# lpc register map
Vendor: Texas Instruments
Peripheral module from a debugger description file (folder tm4e1231h6zrb).
Registers are 32-bit, read-write, no defined reset value unless marked. A register's access mark holds for its fields unless they carry their own. Offsets are as the file gives them; lines under a group give offsets from that group; [hi:lo] are bit positions; {n}, {i} and the like mark numbered series; 'fields as' and 'values as' point back to an identical list; <NAME> marks a mode.

## LPC0 — LPC register addresses
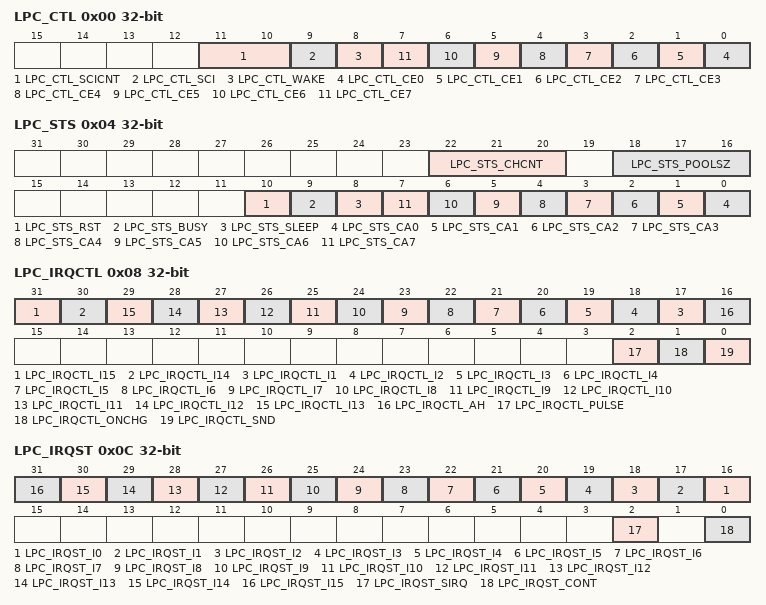
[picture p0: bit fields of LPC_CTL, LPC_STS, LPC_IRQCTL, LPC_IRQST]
0x00 LPC_CTL — LPC Control
  [11:10] LPC_CTL_SCICNT — LPC0SCI Pulse Length
    0=1-clock pulse; 1=2-clock pulse; 2=4-clock pulse; 3=8-clock pulse
  [9] LPC_CTL_SCI — Start LPC0SCI Pulse
  [8] LPC_CTL_WAKE — Wake or Keep Awake the LPC Bus
  [n] LPC_CTL_CE{n} (n=0..7) — Enable Channel {n}
0x04 LPC_STS ro — LPC Status
  [22:20] LPC_STS_CHCNT — Number of Channels
  [18:16] LPC_STS_POOLSZ — Register Pool Size
    1=256 bytes; 2=512 bytes; 3=768 bytes; 4=1024 bytes
  [10] LPC_STS_RST — LPC Bus is in Reset
  [9] LPC_STS_BUSY — LPC is Busy
  [8] LPC_STS_SLEEP — Sleep Mode
  [n] LPC_STS_CA{n} (n=0..7) — Channel {n} Active
0x08 LPC_IRQCTL — LPC IRQ Control
  [31] LPC_IRQCTL_I15 — Manual IRQ15 State
  [30] LPC_IRQCTL_I14 — Manual IRQ14 State
  [n+16] LPC_IRQCTL_I{n} (n=1..13) — Manual IIRQ{n} State
  [16] LPC_IRQCTL_AH — Active High Control
  [2] LPC_IRQCTL_PULSE — Pulse IRQ States
  [1] LPC_IRQCTL_ONCHG — Initiate on Change
  [0] LPC_IRQCTL_SND — Initiate Immediately
0x0C LPC_IRQST ro — LPC IRQ Status
  [n+16] LPC_IRQST_I{n} (n=0..15) — IRQ{n} State
  [2] LPC_IRQST_SIRQ — SERIRQ Transaction Frame Being Processed
  [0] LPC_IRQST_CONT — SERIRQ Continuous Mode
0x10 LPC_CH0CTL — LPC Channel 0 Control
  [31:28] LPC_CH0CTL_IRQSEL2 — IRQ Select 2
  [27:24] LPC_CH0CTL_IRQSEL1 — IRQ Select 1
  [23:20] LPC_CH0CTL_IRQSEL0 — IRQ Select 0
  [19] LPC_CH0CTL_IRQEN2 — IRQ Enable 2
  [19] LPC_CH0CTL_CX — IRQ Enable 2
  [18] LPC_CH0CTL_IRQEN1 — IRQ Enable 1
  [17:16] LPC_CH0CTL_IRQEN0 — IRQ Enable 0
    0=LPC_CH0CTL_IRQEN0_DIS (Trigger disabled); 1=LPC_CH0CTL_IRQEN0_TRIG1 (Trigger 1); 2=LPC_CH0CTL_IRQEN0_TRIG2 (Trigger 2); 3=LPC_CH0CTL_IRQEN0_TRIG3 (Trigger 3)
  [15] LPC_CH0CTL_ARBDIS — Arbitration Disabled
  [13:5] LPC_CH0CTL_OFFSET — Base Offset in Register Pool
  [4:2] LPC_CH0CTL_AMASK — Address Mask for Ranges
    0=4 bytes; 1=8 bytes; 2=16 bytes; 3=32 bytes; 4=64 bytes; 5=128 bytes; 6=256 bytes; 7=512 bytes
  [0] LPC_CH0CTL_TYPE — Channel Type
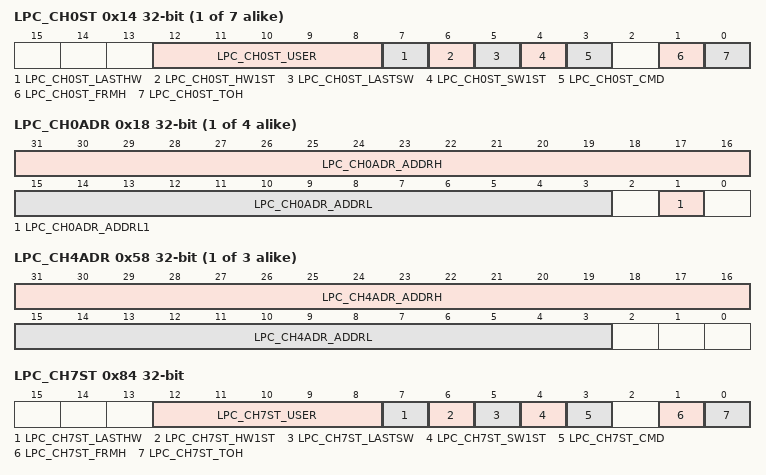
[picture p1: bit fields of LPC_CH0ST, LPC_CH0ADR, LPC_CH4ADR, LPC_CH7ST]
{0x14+0x10*i} LPC_CH{i}ST (i=0..6) — LPC Channel {i} Status
  [12:8] LPC_CH{i}ST_USER — User Data
  [7] LPC_CH{i}ST_LASTHW — Last Host Write
  [6] LPC_CH{i}ST_HW1ST — Host Wrote First
  [5] LPC_CH{i}ST_LASTSW — Last Slave Write
  [4] LPC_CH{i}ST_SW1ST — Slave Wrote First
  [3] LPC_CH{i}ST_CMD — Command or Data
  [1] LPC_CH{i}ST_FRMH — From-Host Transaction
  [0] LPC_CH{i}ST_TOH — To-Host Transaction
{0x18+0x10*i} LPC_CH{i}ADR (i=0..3) — LPC Channel {i} Address
  [31:16] LPC_CH{i}ADR_ADDRH — Upper Address Match
  [15:3] LPC_CH{i}ADR_ADDRL — Lower Address Match
  [1] LPC_CH{i}ADR_ADDRL1 — Endpoint Match Bit 1
0x20 LPC_CH1CTL — LPC Channel 1 Control
  [31:28] LPC_CH1CTL_IRQSEL2 — IRQ Select 2
  [27:24] LPC_CH1CTL_IRQSEL1 — IRQ Select 1
  [23:20] LPC_CH1CTL_IRQSEL0 — IRQ Select 0
  [19] LPC_CH1CTL_IRQEN2 — IRQ Enable 2
  [19] LPC_CH1CTL_CX — IRQ Enable 2
  [18] LPC_CH1CTL_IRQEN1 — IRQ Enable 1
  [17:16] LPC_CH1CTL_IRQEN0 — IRQ Enable 0
    0=LPC_CH1CTL_IRQEN0_DIS (Trigger disabled); 1=LPC_CH1CTL_IRQEN0_TRIG1 (Trigger 1); 2=LPC_CH1CTL_IRQEN0_TRGI2 (Trigger 2); 3=LPC_CH1CTL_IRQEN0_TRGI3 (Trigger 3)
  [15] LPC_CH1CTL_ARBDIS — Arbitration Disabled
  [13:5] LPC_CH1CTL_OFFSET — Base Offset in Register Pool
  [4:2] LPC_CH1CTL_AMASK — Address Mask for Ranges
    values as LPC_CH0CTL.LPC_CH0CTL_AMASK
  [0] LPC_CH1CTL_TYPE — Channel Type
0x30 LPC_CH2CTL — LPC Channel 2 Control
  [31:28] LPC_CH2CTL_IRQSEL2 — IRQ Select 2
  [27:24] LPC_CH2CTL_IRQSEL1 — IRQ Select 1
  [23:20] LPC_CH2CTL_IRQSEL0 — IRQ Select 0
  [19] LPC_CH2CTL_CX — IRQ Enable 2
  [19] LPC_CH2CTL_IRQEN2 — IRQ Enable 2
  [18] LPC_CH2CTL_IRQEN1 — IRQ Enable 1
  [17:16] LPC_CH2CTL_IRQEN0 — IRQ Enable 0
    0=LPC_CH2CTL_IRQEN0_DIS (Trigger disabled); 1=LPC_CH2CTL_IRQEN0_TRIG1 (Trigger 1); 2=LPC_CH2CTL_IRQEN0_TRIG2 (Trigger 2); 3=LPC_CH2CTL_IRQEN0_TRIG3 (Trigger 3)
  [15] LPC_CH2CTL_ARBDIS — Arbitration Disabled
  [13:5] LPC_CH2CTL_OFFSET — Base Offset in Register Pool
  [4:2] LPC_CH2CTL_AMASK — Address Mask for Ranges
    values as LPC_CH0CTL.LPC_CH0CTL_AMASK
  [0] LPC_CH2CTL_TYPE — Channel Type
0x40 LPC_CH3CTL — LPC Channel 3 Control
  [31:28] LPC_CH3CTL_IRQSEL2 — IRQ Select 2
  [27:24] LPC_CH3CTL_IRQSEL1 — IRQ Select 1
  [23:20] LPC_CH3CTL_IRQSEL0 — IRQ Select 0
  [19] LPC_CH3CTL_IRQEN2 — IRQ Enable 2
  [19] LPC_CH3CTL_CX — IRQ Enable 2
  [18] LPC_CH3CTL_IRQEN1 — IRQ Enable 1
  [17:16] LPC_CH3CTL_IRQEN0 — IRQ Enable 0
    0=LPC_CH3CTL_IRQEN0_DIS (Trigger disabled); 1=LPC_CH3CTL_IRQEN0_TRIG1 (Trigger 1); 2=LPC_CH3CTL_IRQEN0_TRIG2 (Trigger 2); 3=LPC_CH3CTL_IRQEN0_TRIG3 (Trigger 3)
  [15] LPC_CH3CTL_ARBDIS — Arbitration Disabled
  [13:5] LPC_CH3CTL_OFFSET — Base Offset in Register Pool
  [4:2] LPC_CH3CTL_AMASK — Address Mask for Ranges
    values as LPC_CH0CTL.LPC_CH0CTL_AMASK
  [0] LPC_CH3CTL_TYPE — Channel Type
0x50 LPC_CH4CTL — LPC Channel 4 Control
  [31:28] LPC_CH4CTL_IRQSEL2 — IRQ Select 2
  [27:24] LPC_CH4CTL_IRQSEL1 — IRQ Select 1
  [23:20] LPC_CH4CTL_IRQSEL0 — IRQ Select 0
  [19] LPC_CH4CTL_CX — IRQ Enable 2
  [19] LPC_CH4CTL_IRQEN2 — IRQ Enable 2
  [18] LPC_CH4CTL_IRQEN1 — IRQ Enable 1
  [17:16] LPC_CH4CTL_IRQEN0 — IRQ Enable 0
    0=LPC_CH4CTL_IRQEN0_DIS (Trigger disabled); 1=LPC_CH4CTL_IRQEN0_TRIG1 (Trigger 1); 2=LPC_CH4CTL_IRQEN0_TRIG2 (Trigger 2); 3=LPC_CH4CTL_IRQEN0_TRIG3 (Trigger 3)
  [15] LPC_CH4CTL_ARBDIS — Arbitration Disabled
  [13:5] LPC_CH4CTL_OFFSET — Base Offset in Register Pool
  [4:2] LPC_CH4CTL_AMASK — Address Mask for Ranges
    values as LPC_CH0CTL.LPC_CH0CTL_AMASK
  [0] LPC_CH4CTL_TYPE — Channel Type
{0x18+0x10*i} LPC_CH{i}ADR (i=4..6) — LPC Channel {i} Address
  [31:16] LPC_CH{i}ADR_ADDRH — Upper Address Match
  [15:3] LPC_CH{i}ADR_ADDRL — Lower Address Match
0x60 LPC_CH5CTL — LPC Channel 5 Control
  [31:28] LPC_CH5CTL_IRQSEL2 — IRQ Select 2
  [27:24] LPC_CH5CTL_IRQSEL1 — IRQ Select 1
  [23:20] LPC_CH5CTL_IRQSEL0 — IRQ Select 0
  [19] LPC_CH5CTL_IRQEN2 — IRQ Enable 2
  [19] LPC_CH5CTL_CX — IRQ Enable 2
  [18] LPC_CH5CTL_IRQEN1 — IRQ Enable 1
  [17:16] LPC_CH5CTL_IRQEN0 — IRQ Enable 0
    0=LPC_CH5CTL_IRQEN0_DIS (Trigger disabled); 1=LPC_CH5CTL_IRQEN0_TRIG1 (Trigger 1); 2=LPC_CH5CTL_IRQEN0_TRIG2 (Trigger 2); 3=LPC_CH5CTL_IRQEN0_TRIG3 (Trigger 3)
  [15] LPC_CH5CTL_ARBDIS — Arbitration Disabled
  [13:5] LPC_CH5CTL_OFFSET — Base Offset in Register Pool
  [4:2] LPC_CH5CTL_AMASK — Address Mask for Ranges
    values as LPC_CH0CTL.LPC_CH0CTL_AMASK
  [0] LPC_CH5CTL_TYPE — Channel Type
0x70 LPC_CH6CTL — LPC Channel 6 Control
  [31:28] LPC_CH6CTL_IRQSEL2 — IRQ Select 2
  [27:24] LPC_CH6CTL_IRQSEL1 — IRQ Select 1
  [23:20] LPC_CH6CTL_IRQSEL0 — IRQ Select 0
  [19] LPC_CH6CTL_CX — IRQ Enable 2
  [19] LPC_CH6CTL_IRQEN2 — IRQ Enable 2
  [18] LPC_CH6CTL_IRQEN1 — IRQ Enable 1
  [17:16] LPC_CH6CTL_IRQEN0 — IRQ Enable 0
    0=LPC_CH6CTL_IRQEN0_DIS (Trigger disabled); 1=LPC_CH6CTL_IRQEN0_TRIG1 (Trigger 1); 2=LPC_CH6CTL_IRQEN0_TRIG2 (Trigger 2); 3=LPC_CH6CTL_IRQEN0_TRIG3 (Trigger 3)
  [15] LPC_CH6CTL_ARBDIS — Arbitration Disabled
  [13:5] LPC_CH6CTL_OFFSET — Base Offset in Register Pool
  [4:2] LPC_CH6CTL_AMASK — Address Mask for Ranges
    values as LPC_CH0CTL.LPC_CH0CTL_AMASK
  [0] LPC_CH6CTL_TYPE — Channel Type
0x80 LPC_CH7CTL — LPC Channel 7 / COMx Control
  [31:28] LPC_CH7CTL_IRQSEL2 — IRQ Select 2
  [27:24] LPC_CH7CTL_IRQSEL1 — IRQ Select 1
  [23:20] LPC_CH7CTL_IRQSEL0 — IRQ Select 0
  [19] LPC_CH7CTL_CX — IRQ Enable 2
  [19] LPC_CH7CTL_IRQEN2 — IRQ Enable 2
  [18] LPC_CH7CTL_IRQEN1 — IRQ Enable 1
  [17:16] LPC_CH7CTL_IRQEN0 — IRQ Enable 0
    0=LPC_CH7CTL_IRQEN0_AUTO (Trigger disabled); 1=LPC_CH7CTL_IRQEN0_MST (Trigger 1); 2=LPC_CH7CTL_IRQEN0_SLV (Trigger 2); 3=LPC_CH7CTL_IRQEN0_TRIG3 (Trigger 3)
  [15] LPC_CH7CTL_ARBDIS — Arbitration Disabled
  [13:5] LPC_CH7CTL_OFFSET — Base Offset in Register Pool
  [4:2] LPC_CH7CTL_AMASK — Address Mask for Ranges
    values as LPC_CH0CTL.LPC_CH0CTL_AMASK
  [0] LPC_CH7CTL_TYPE — Channel Type
0x84 LPC_CH7ST — LPC Channel 7 / COMx Status
  [12:8] LPC_CH7ST_USER — User Data
  [7] LPC_CH7ST_LASTHW — Last Host Write
  [6] LPC_CH7ST_HW1ST — Host Wrote First
  [5] LPC_CH7ST_LASTSW — Last Slave Write
  [4] LPC_CH7ST_SW1ST — Slave Wrote First
  [3] LPC_CH7ST_CMD — Command or Data
  [1] LPC_CH7ST_FRMH — From-Host Transaction
  [0] LPC_CH7ST_TOH — To-Host Transaction
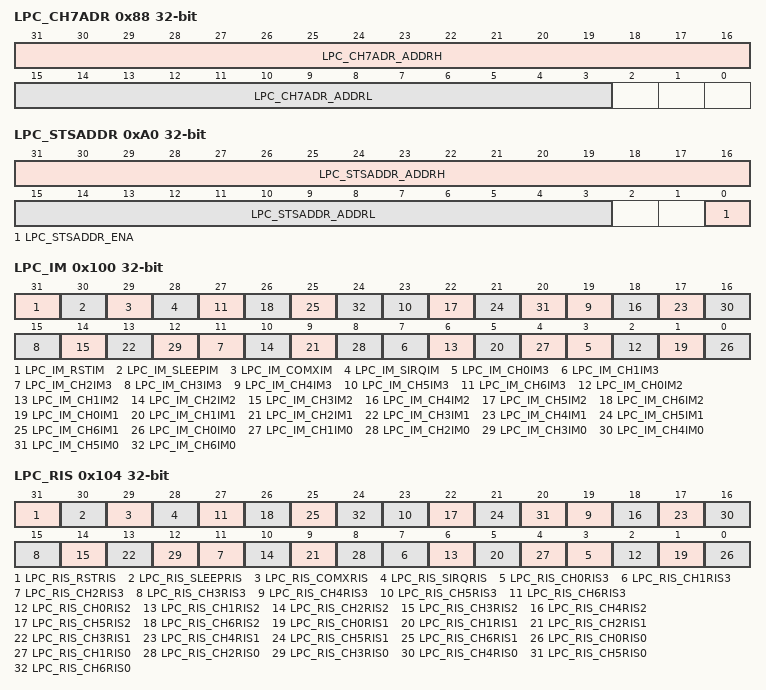
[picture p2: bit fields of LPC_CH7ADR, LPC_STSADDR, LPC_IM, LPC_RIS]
0x88 LPC_CH7ADR — LPC Channel 7 / COMx Address
  [31:16] LPC_CH7ADR_ADDRH — Upper Address Match
  [15:3] LPC_CH7ADR_ADDRL — Lower Address Match
0xA0 LPC_STSADDR — LPC Status Block Address
  [31:16] LPC_STSADDR_ADDRH — Upper Address Match
  [15:3] LPC_STSADDR_ADDRL — Lower Address Match
  [0] LPC_STSADDR_ENA — Enable Status Block
0x100 LPC_IM — LPC Interrupt Mask
  [31] LPC_IM_RSTIM — Reset State Interrupt Mask
  [30] LPC_IM_SLEEPIM — Sleep State Interrupt Mask
  [29] LPC_IM_COMXIM — COMx Interrupt Mask
  [28] LPC_IM_SIRQIM — SERIRQ Frame Complete Interrupt Mask
  [4n+3] LPC_IM_CH{n}IM3 (n=0..6) — Channel {n} Interrupt Mask 3
  [4n+2] LPC_IM_CH{n}IM2 (n=0..6) — Channel {n} Interrupt Mask 2
  [4n+1] LPC_IM_CH{n}IM1 (n=0..6) — Channel {n} Interrupt Mask 1
  [4n] LPC_IM_CH{n}IM0 (n=0..6) — Channel {n} Interrupt Mask 0
0x104 LPC_RIS ro — LPC Raw Interrupt Status
  [31] LPC_RIS_RSTRIS — Reset State Raw Interrupt Status
  [30] LPC_RIS_SLEEPRIS — Sleep State Raw Interrupt Status
  [29] LPC_RIS_COMXRIS — COMx Raw Interrupt Status
  [28] LPC_RIS_SIRQRIS — SERIRQ Frame Complete Raw Interrupt Status
  [4n+3] LPC_RIS_CH{n}RIS3 (n=0..6) — Channel {n} Raw Interrupt Status 3
  [4n+2] LPC_RIS_CH{n}RIS2 (n=0..6) — Channel {n} Raw Interrupt Status 2
  [4n+1] LPC_RIS_CH{n}RIS1 (n=0..6) — Channel {n} Raw Interrupt Status 1
  [4n] LPC_RIS_CH{n}RIS0 (n=0..6) — Channel {n} Raw Interrupt Status 0
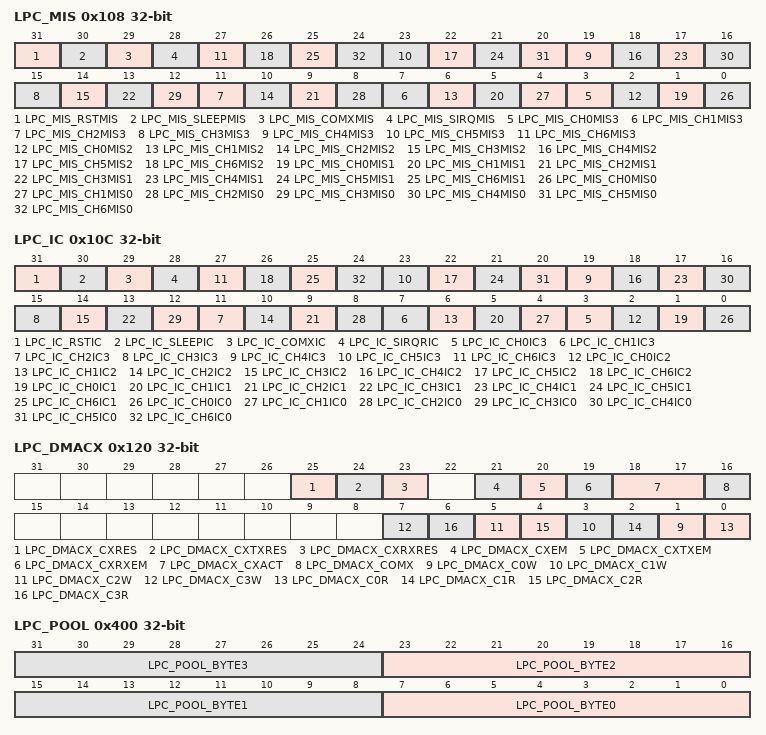
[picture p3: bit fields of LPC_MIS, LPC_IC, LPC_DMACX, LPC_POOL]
0x108 LPC_MIS ro — LPC Masked Interrupt Status
  [31] LPC_MIS_RSTMIS — Reset State Masked Interrupt Status
  [30] LPC_MIS_SLEEPMIS — Sleep State Masked Interrupt Status
  [29] LPC_MIS_COMXMIS — COMx Masked Interrupt Status
  [28] LPC_MIS_SIRQMIS — SERIRQ Frame Complete Masked Interrupt Status
  [4n+3] LPC_MIS_CH{n}MIS3 (n=0..6) — Channel {n} Masked Interrupt Status 3
  [4n+2] LPC_MIS_CH{n}MIS2 (n=0..6) — Channel {n} Masked Interrupt Status 2
  [4n+1] LPC_MIS_CH{n}MIS1 (n=0..6) — Channel {n} Masked Interrupt Status 1
  [4n] LPC_MIS_CH{n}MIS0 (n=0..6) — Channel {n} Masked Interrupt Status 0
0x10C LPC_IC wo — LPC Interrupt Clear
  [31] LPC_IC_RSTIC — Reset State Interrupt Clear
  [30] LPC_IC_SLEEPIC — Sleep State Interrupt Clear
  [29] LPC_IC_COMXIC — COMx Interrupt Clear
  [28] LPC_IC_SIRQRIC — SERIRQ Frame Complete Interrupt Clear
  [4n+3] LPC_IC_CH{n}IC3 (n=0..6) — Channel {n} Interrupt Clear 3
  [4n+2] LPC_IC_CH{n}IC2 (n=0..6) — Channel {n} Interrupt Clear 2
  [4n+1] LPC_IC_CH{n}IC1 (n=0..6) — Channel {n} Interrupt Clear 1
  [4n] LPC_IC_CH{n}IC0 (n=0..6) — Channel {n} Interrupt Clear 0
0x120 LPC_DMACX — LPC DMA and COMx Control
  [25] LPC_DMACX_CXRES — Raw Event State for COMx
  [24] LPC_DMACX_CXTXRES — Raw Event State for COMx TX
  [23] LPC_DMACX_CXRXRES — Raw Event State for COMx RX
  [21] LPC_DMACX_CXEM — Event Mask for COMx
  [20] LPC_DMACX_CXTXEM — Event Mask for COMx TX
  [19] LPC_DMACX_CXRXEM — Event Mask for COMx RX
  [18:17] LPC_DMACX_CXACT — COMx Action
    0=LPC_DMACX_CXACT_FRMHNML (Normal from-host model); 1=LPC_DMACX_CXACT_FRMHIGN (From-host buffer status empty); 2=LPC_DMACX_CXACT_FRMHDMA (Trigger uDMA); 3=LPC_DMACX_CXACT_UARTDMA (COMx DMA model with UART)
  [16] LPC_DMACX_COMX — COMx Handling
  [2n+1] LPC_DMACX_C{n}W (n=0..3) — Write Control for Channel {n}
  [2n] LPC_DMACX_C{n}R (n=0..3) — Read Control for Channel {n}
0x400 LPC_POOL — LPC Register Pool
  [8n+7:8n] LPC_POOL_BYTE{n} (n=0..3) — Byte {n}
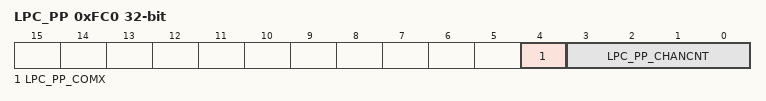
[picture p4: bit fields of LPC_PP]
0xFC0 LPC_PP ro — LPC Peripheral Properties
  [4] LPC_PP_COMX — COMx Support Available
  [3:0] LPC_PP_CHANCNT — Number of Channels (Excluding COMx)
